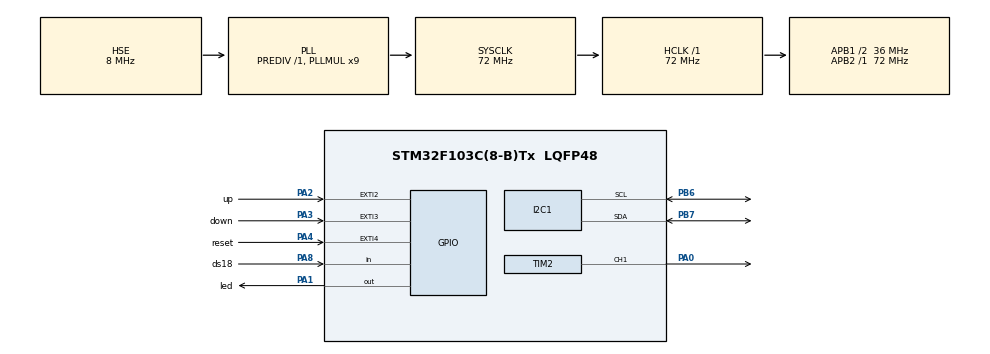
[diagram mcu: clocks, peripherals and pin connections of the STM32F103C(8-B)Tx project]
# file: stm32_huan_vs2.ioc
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Mcu.Family=STM32F1
Mcu.Name=STM32F103C(8-B)Tx
Mcu.Package=LQFP48
NVIC.PriorityGroup=NVIC_PRIORITYGROUP_4
PA0-WKUP.Signal=S_TIM2_CH1_ETR
PA1.GPIO_Label=led
PA1.Signal=GPIO_Output
PA13.Mode=Serial_Wire
PA13.Signal=SYS_JTMS-SWDIO
PA14.Mode=Serial_Wire
PA14.Signal=SYS_JTCK-SWCLK
PA2.GPIO_Label=up
PA2.Signal=GPXTI2
PA3.GPIO_Label=down
PA3.Signal=GPXTI3
PA4.GPIO_Label=reset
PA4.Signal=GPXTI4
PA8.GPIO_Label=ds18
PA8.Signal=GPIO_Input
PB6.Mode=I2C
PB6.Signal=I2C1_SCL
PB7.Mode=I2C
PB7.Signal=I2C1_SDA
PD0-OSC_IN.Mode=HSE-External-Oscillator
PD0-OSC_IN.Signal=RCC_OSC_IN
PD1-OSC_OUT.Mode=HSE-External-Oscillator
PD1-OSC_OUT.Signal=RCC_OSC_OUT
ProjectManager.HeapSize=0x200
ProjectManager.StackSize=0x400
ProjectManager.TargetToolchain=STM32CubeIDE
RCC.AHBFreq_Value=72000000
RCC.APB1CLKDivider=RCC_HCLK_DIV2
RCC.APB1Freq_Value=36000000
RCC.APB1TimFreq_Value=72000000
RCC.APB2Freq_Value=72000000
RCC.APB2TimFreq_Value=72000000
RCC.HCLKFreq_Value=72000000
RCC.PLLMUL=RCC_PLL_MUL9
RCC.PLLSourceVirtual=RCC_PLLSOURCE_HSE
RCC.SYSCLKFreq_VALUE=72000000
RCC.SYSCLKSource=RCC_SYSCLKSOURCE_PLLCLK
RCC.USBFreq_Value=72000000
SH.S_TIM2_CH1_ETR.0=TIM2_CH1,PWM Generation1 CH1
TIM1.Period=999
TIM1.Prescaler=71
TIM2.Channel-PWM\ Generation1\ CH1=TIM_CHANNEL_1
VP_TIM1_VS_ClockSourceINT.Mode=Internal
board=custom

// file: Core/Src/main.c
#include "main.h"
#include"I2C_LCD.h"
#include"ds18b20.h"
#include<stdio.h>

I2C_HandleTypeDef hi2c1;

TIM_HandleTypeDef htim1;
TIM_HandleTypeDef htim2;

void SystemClock_Config(void);
static void MX_GPIO_Init(void);
static void MX_I2C1_Init(void);
static void MX_TIM1_Init(void);
static void MX_TIM2_Init(void);
/* USER CODE BEGIN PFP */
volatile int temp_set = 25;

void Display_Temp(void) {
    char buffer[16];
    float temp = DS18B20_GetTemperature();
    if (temp != -1000) {
        sprintf(buffer, "Temp : %.2f C", temp);
    } else {
        sprintf(buffer, "Sensor Error!");
    }
    LCD_Clear();
    LCD_PutCursor(0, 0);
    LCD_SendString(buffer);
// in ra temp_set
    sprintf(buffer, "Temp Set : %d C", temp_set);
    LCD_PutCursor(1, 0);
    LCD_SendString(buffer);
}

void Read_Buttons() {

        if (HAL_GPIO_ReadPin(up_GPIO_Port, up_Pin) == 0) {
            temp_set++;
            Display_Temp();
        }

        if (HAL_GPIO_ReadPin(down_GPIO_Port, down_Pin) == 0) {
            temp_set--;
            Display_Temp();
        }
        if (HAL_GPIO_ReadPin(reset_GPIO_Port, reset_Pin) == 0) {
        	temp_set = 25;
        	Display_Temp();
        }
HAL_Delay(50);
}

/* USER CODE END 0 */

int main(void)
{

  HAL_Init();
  SystemClock_Config();
  MX_GPIO_Init();
  MX_I2C1_Init();
  MX_TIM1_Init();
  MX_TIM2_Init();
  /* USER CODE BEGIN 2 */
HAL_TIM_PWM_Start(&htim2, TIM_CHANNEL_1);
HAL_TIM_Base_Start(&htim1);
LCD_Init();
DWT_Delay_Init();

LCD_SendString("..INSTALLING*.......");
HAL_Delay(2000);
 LCD_Clear();
  /* USER CODE END 2 */
 float temp ;
  /* Infinite loop */
  /* USER CODE BEGIN WHILE */
 while (1) {
     Read_Buttons();
     temp = DS18B20_GetTemperature();
     Display_Temp(); // Hiển thị nhiệt độ lên LCD

     int fan_speed = (temp > temp_set + 5) ? 2 : (temp > temp_set ? 1 : 0);

     switch (fan_speed) {
         case 2: // Nhiệt độ cao (quá nóng)
             __HAL_TIM_SET_COMPARE(&htim2, TIM_CHANNEL_1, 999); // Quạt chạy 100%
             HAL_GPIO_WritePin(led_GPIO_Port, led_Pin, GPIO_PIN_RESET); // Đèn tắt
             break;

         case 1: // Nhiệt độ hơi cao
             __HAL_TIM_SET_COMPARE(&htim2, TIM_CHANNEL_1, 300); // Quạt chạy 50%
             HAL_GPIO_WritePin(led_GPIO_Port, led_Pin, GPIO_PIN_RESET); // Đèn bật
             break;

         case 0: // Nhiệt độ bình thường
             __HAL_TIM_SET_COMPARE(&htim2, TIM_CHANNEL_1, 0); // Quạt tắt
             HAL_GPIO_WritePin(led_GPIO_Port, led_Pin, GPIO_PIN_SET); // Đèn bật
             break;
     }
 }

  /* USER CODE END 3 */
}

void SystemClock_Config(void)
{
  RCC_OscInitTypeDef RCC_OscInitStruct = {0};
  RCC_ClkInitTypeDef RCC_ClkInitStruct = {0};

  /** Initializes the RCC Oscillators according to the specified parameters
  * in the RCC_OscInitTypeDef structure.
  */
  RCC_OscInitStruct.OscillatorType = RCC_OSCILLATORTYPE_HSE;
  RCC_OscInitStruct.HSEState = RCC_HSE_ON;
  RCC_OscInitStruct.HSEPredivValue = RCC_HSE_PREDIV_DIV1;
  RCC_OscInitStruct.HSIState = RCC_HSI_ON;
  RCC_OscInitStruct.PLL.PLLState = RCC_PLL_ON;
  RCC_OscInitStruct.PLL.PLLSource = RCC_PLLSOURCE_HSE;
  RCC_OscInitStruct.PLL.PLLMUL = RCC_PLL_MUL9;
  if (HAL_RCC_OscConfig(&RCC_OscInitStruct) != HAL_OK)
  {
    Error_Handler();
  }

  /** Initializes the CPU, AHB and APB buses clocks
  */
  RCC_ClkInitStruct.ClockType = RCC_CLOCKTYPE_HCLK|RCC_CLOCKTYPE_SYSCLK
                              |RCC_CLOCKTYPE_PCLK1|RCC_CLOCKTYPE_PCLK2;
  RCC_ClkInitStruct.SYSCLKSource = RCC_SYSCLKSOURCE_PLLCLK;
  RCC_ClkInitStruct.AHBCLKDivider = RCC_SYSCLK_DIV1;
  RCC_ClkInitStruct.APB1CLKDivider = RCC_HCLK_DIV2;
  RCC_ClkInitStruct.APB2CLKDivider = RCC_HCLK_DIV1;

  if (HAL_RCC_ClockConfig(&RCC_ClkInitStruct, FLASH_LATENCY_2) != HAL_OK)
  {
    Error_Handler();
  }
}

static void MX_I2C1_Init(void)
{

  hi2c1.Instance = I2C1;
  hi2c1.Init.ClockSpeed = 100000;
  hi2c1.Init.DutyCycle = I2C_DUTYCYCLE_2;
  hi2c1.Init.OwnAddress1 = 0;
  hi2c1.Init.AddressingMode = I2C_ADDRESSINGMODE_7BIT;
  hi2c1.Init.DualAddressMode = I2C_DUALADDRESS_DISABLE;
  hi2c1.Init.OwnAddress2 = 0;
  hi2c1.Init.GeneralCallMode = I2C_GENERALCALL_DISABLE;
  hi2c1.Init.NoStretchMode = I2C_NOSTRETCH_DISABLE;
  if (HAL_I2C_Init(&hi2c1) != HAL_OK)
  {
    Error_Handler();
  }

}

static void MX_TIM1_Init(void)
{

  TIM_ClockConfigTypeDef sClockSourceConfig = {0};
  TIM_MasterConfigTypeDef sMasterConfig = {0};

  htim1.Instance = TIM1;
  htim1.Init.Prescaler = 71;
  htim1.Init.CounterMode = TIM_COUNTERMODE_UP;
  htim1.Init.Period = 999;
  htim1.Init.ClockDivision = TIM_CLOCKDIVISION_DIV1;
  htim1.Init.RepetitionCounter = 0;
  htim1.Init.AutoReloadPreload = TIM_AUTORELOAD_PRELOAD_DISABLE;
  if (HAL_TIM_Base_Init(&htim1) != HAL_OK)
  {
    Error_Handler();
  }
  sClockSourceConfig.ClockSource = TIM_CLOCKSOURCE_INTERNAL;
  if (HAL_TIM_ConfigClockSource(&htim1, &sClockSourceConfig) != HAL_OK)
  {
    Error_Handler();
  }
  sMasterConfig.MasterOutputTrigger = TIM_TRGO_RESET;
  sMasterConfig.MasterSlaveMode = TIM_MASTERSLAVEMODE_DISABLE;
  if (HAL_TIMEx_MasterConfigSynchronization(&htim1, &sMasterConfig) != HAL_OK)
  {
    Error_Handler();
  }

}

static void MX_TIM2_Init(void)
{

  TIM_MasterConfigTypeDef sMasterConfig = {0};
  TIM_OC_InitTypeDef sConfigOC = {0};

  htim2.Instance = TIM2;
  htim2.Init.Prescaler = 71;
  htim2.Init.CounterMode = TIM_COUNTERMODE_UP;
  htim2.Init.Period = 999;
  htim2.Init.ClockDivision = TIM_CLOCKDIVISION_DIV1;
  htim2.Init.AutoReloadPreload = TIM_AUTORELOAD_PRELOAD_DISABLE;
  if (HAL_TIM_PWM_Init(&htim2) != HAL_OK)
  {
    Error_Handler();
  }
  sMasterConfig.MasterOutputTrigger = TIM_TRGO_RESET;
  sMasterConfig.MasterSlaveMode = TIM_MASTERSLAVEMODE_DISABLE;
  if (HAL_TIMEx_MasterConfigSynchronization(&htim2, &sMasterConfig) != HAL_OK)
  {
    Error_Handler();
  }
  sConfigOC.OCMode = TIM_OCMODE_PWM1;
  sConfigOC.Pulse = 0;
  sConfigOC.OCPolarity = TIM_OCPOLARITY_HIGH;
  sConfigOC.OCFastMode = TIM_OCFAST_DISABLE;
  if (HAL_TIM_PWM_ConfigChannel(&htim2, &sConfigOC, TIM_CHANNEL_1) != HAL_OK)
  {
    Error_Handler();
  }
  HAL_TIM_MspPostInit(&htim2);

}

static void MX_GPIO_Init(void)
{
  GPIO_InitTypeDef GPIO_InitStruct = {0};

  /* GPIO Ports Clock Enable */
  __HAL_RCC_GPIOD_CLK_ENABLE();
  __HAL_RCC_GPIOA_CLK_ENABLE();
  __HAL_RCC_GPIOB_CLK_ENABLE();

  /*Configure GPIO pin Output Level */
  HAL_GPIO_WritePin(GPIOA, led_Pin|ds18_Pin, GPIO_PIN_RESET);

  /*Configure GPIO pins : led_Pin ds18_Pin */
  GPIO_InitStruct.Pin = led_Pin|ds18_Pin;
  GPIO_InitStruct.Mode = GPIO_MODE_OUTPUT_PP;
  GPIO_InitStruct.Pull = GPIO_NOPULL;
  GPIO_InitStruct.Speed = GPIO_SPEED_FREQ_LOW;
  HAL_GPIO_Init(GPIOA, &GPIO_InitStruct);

  /*Configure GPIO pins : up_Pin down_Pin */
  /* Configure GPIO pins for buttons with Pull-Up */
  GPIO_InitStruct.Pin = up_Pin | down_Pin | reset_Pin;
  GPIO_InitStruct.Mode = GPIO_MODE_INPUT;  // Chuyển sang chế độ input thông thường
  GPIO_InitStruct.Pull = GPIO_NOPULL;      // Kích hoạt chế độ pull-up nội
  HAL_GPIO_Init(GPIOA, &GPIO_InitStruct);

}

void Error_Handler(void)
{
  __disable_irq();
  while (1)
  {
  }
}
